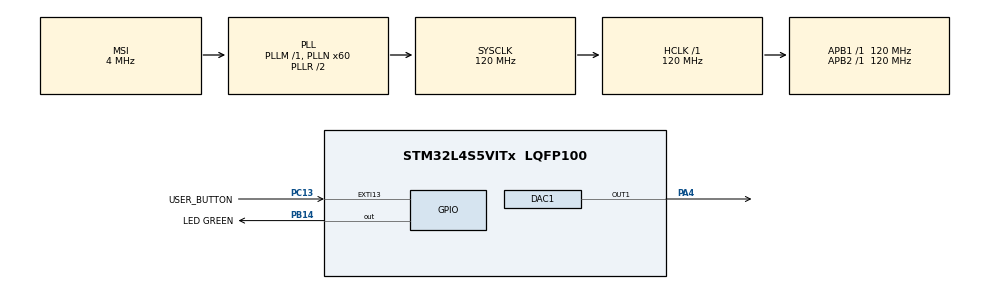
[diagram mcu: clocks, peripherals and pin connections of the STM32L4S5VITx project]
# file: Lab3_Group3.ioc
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DAC1.DAC_Trigger-DAC_OUT1=DAC_TRIGGER_T2_TRGO
Dma.DAC1_CH1.0.Direction=DMA_MEMORY_TO_PERIPH
Dma.DAC1_CH1.0.EventEnable=DISABLE
Dma.DAC1_CH1.0.Instance=DMA1_Channel1
Dma.DAC1_CH1.0.MemDataAlignment=DMA_MDATAALIGN_HALFWORD
Dma.DAC1_CH1.0.MemInc=DMA_MINC_ENABLE
Dma.DAC1_CH1.0.Mode=DMA_CIRCULAR
Dma.DAC1_CH1.0.PeriphDataAlignment=DMA_PDATAALIGN_HALFWORD
Dma.DAC1_CH1.0.PeriphInc=DMA_PINC_DISABLE
Dma.DAC1_CH1.0.Polarity=HAL_DMAMUX_REQUEST_GEN_RISING
Dma.DAC1_CH1.0.Priority=DMA_PRIORITY_LOW
Dma.DAC1_CH1.0.RequestNumber=1
Dma.DAC1_CH1.0.SignalID=NONE
Dma.DAC1_CH1.0.SyncEnable=DISABLE
Dma.DAC1_CH1.0.SyncPolarity=HAL_DMAMUX_SYNC_NO_EVENT
Dma.DAC1_CH1.0.SyncRequestNumber=1
Dma.DAC1_CH1.0.SyncSignalID=NONE
Dma.Request0=DAC1_CH1
Mcu.Family=STM32L4
Mcu.Name=STM32L4S5VITx
Mcu.Package=LQFP100
NVIC.DMA1_Channel1_IRQn=true\:0\:0\:false\:false\:true\:false\:true
NVIC.EXTI15_10_IRQn=true\:0\:0\:false\:false\:true\:true\:true
NVIC.PriorityGroup=NVIC_PRIORITYGROUP_0
NVIC.TIM2_IRQn=true\:0\:0\:false\:false\:true\:true\:true
PA13\ (JTMS/SWDIO).Mode=Serial_Wire
PA13\ (JTMS/SWDIO).Signal=SYS_JTMS-SWDIO
PA14\ (JTCK/SWCLK).Mode=Serial_Wire
PA14\ (JTCK/SWCLK).Signal=SYS_JTCK-SWCLK
PA4.Signal=COMP_DAC11_group
PB14.GPIO_Label=LED GREEN
PB14.Signal=GPIO_Output
PC13.GPIO_Label=USER_BUTTON
PC13.Signal=GPXTI13
ProjectManager.HeapSize=0x200
ProjectManager.StackSize=0x400
ProjectManager.TargetToolchain=STM32CubeIDE
RCC.ADCFreq_Value=48000000
RCC.AHBFreq_Value=120000000
RCC.APB1Freq_Value=120000000
RCC.APB1TimFreq_Value=120000000
RCC.APB2Freq_Value=120000000
RCC.APB2TimFreq_Value=120000000
RCC.CortexFreq_Value=120000000
RCC.HCLKFreq_Value=120000000
RCC.HSE_VALUE=8000000
RCC.HSI48_VALUE=48000000
RCC.HSI_VALUE=16000000
RCC.LSE_VALUE=32768
RCC.MSI_VALUE=4000000
RCC.PLLN=60
RCC.PLLSAI1N=24
RCC.SYSCLKFreq_VALUE=120000000
RCC.SYSCLKSource=RCC_SYSCLKSOURCE_PLLCLK
RCC.USBFreq_Value=48000000
RCC.VCOOutputFreq_Value=240000000
SH.COMP_DAC11_group.0=DAC1_OUT1,DAC_OUT1
TIM2.Period=2500
TIM2.TIM_MasterOutputTrigger=TIM_TRGO_UPDATE
VP_TIM2_VS_ClockSourceINT.Mode=Internal
board=B-L4S5I-IOT01A

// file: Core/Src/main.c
/* USER CODE BEGIN Header */
/**
  ******************************************************************************
  * @file           : main.c
  * @brief          : Main program body
  ******************************************************************************
  * @attention
  *
  * <h2><center>&copy; Copyright (c) 2021 STMicroelectronics.
  * All rights reserved.</center></h2>
  *
  * This software component is licensed by ST under BSD 3-Clause license,
  * the "License"; You may not use this file except in compliance with the
  * License. You may obtain a copy of the License at:
  *                        opensource.org/licenses/BSD-3-Clause
  *
  ******************************************************************************
  */
/* USER CODE END Header */
#include "main.h"

/* USER CODE BEGIN Includes */
#include "arm_math.h"
#include "lab3part1utils.h"
/* USER CODE END Includes */

/* USER CODE BEGIN PTD */
#define ITM_Port32(n) (*((volatile unsigned long *) (0xE0000000+4*n)))
/* USER CODE END PTD */

/* USER CODE BEGIN PM */
#define MAX_8 255
#define MAX_12 4095
//#define PARTONE 1
//#define PARTTWO_TIMER 2
//#define PARTTWO_DMA 3
#define PARTTWO_MOREDMA 4
/* USER CODE END PM */

DAC_HandleTypeDef hdac1;
DMA_HandleTypeDef hdma_dac1_ch1;

TIM_HandleTypeDef htim2;

void SystemClock_Config(void);
static void MX_GPIO_Init(void);
static void MX_DMA_Init(void);
static void MX_DAC1_Init(void);
static void MX_TIM2_Init(void);

/* USER CODE BEGIN 0 */
uint8_t mode = 0;
#if PARTTWO_DMA || PARTTWO_TIMER
uint8_t sin_idx = 0;
uint16_t sin_lookup_C6[45]; // 1046.5 Hz, sample rate = 48kHz
uint16_t sin_lookup_D6[40]; // 1174.66 Hz,
uint16_t sin_lookup_E6[36]; // 1318.51 Hz,
uint16_t sin_lookup_F6[34]; // 1396.91 Hz,
uint16_t sin_lookup_G6[30]; // 1567.98 Hz,
uint16_t sin_lookup_A6[27]; // 1760.00 Hz,
#else
uint16_t sin_lookup_chord[180]; // lcm(45, 36, 30)
uint16_t sin_lookup_C6[180]; // 1046.5 Hz, sample rate = 48kHz
uint16_t sin_lookup_E6[180]; // 1318.51 Hz,
uint16_t sin_lookup_G6[180]; // 1567.98 Hz,
#endif

/* USER CODE END 0 */

int main(void)
{
  /* USER CODE BEGIN 1 */
#if PARTTWO_DMA || PARTTWO_TIMER
	  uint8_t lookup_len = sizeof(sin_lookup_C6)/sizeof(sin_lookup_C6[0]);
	  for (int i = 0; i < lookup_len; i++){
	  	 sin_lookup_C6[i] = (MAX_12*0.6*(arm_sin_f32(6.283*i/lookup_len)+1));
	  }
	  lookup_len = sizeof(sin_lookup_D6)/sizeof(sin_lookup_D6[0]);
	  for (int i = 0; i < lookup_len; i++){
	  	 sin_lookup_D6[i] = (MAX_12*0.6*(arm_sin_f32(6.283*i/lookup_len)+1));
	  }
	  lookup_len = sizeof(sin_lookup_E6)/sizeof(sin_lookup_E6[0]);
	  for (int i = 0; i < lookup_len; i++){
	  	 sin_lookup_E6[i] =  (MAX_12*0.6*(arm_sin_f32(6.283*i/lookup_len)+1));
	  }
	  lookup_len = sizeof(sin_lookup_F6)/sizeof(sin_lookup_F6[0]);
	  for (int i = 0; i < lookup_len; i++){
	  	 sin_lookup_F6[i] =(MAX_12*0.6*(arm_sin_f32(6.283*i/lookup_len)+1));
	  }
	  lookup_len = sizeof(sin_lookup_G6)/sizeof(sin_lookup_G6[0]);
	  for (int i = 0; i < lookup_len; i++){
	  	 sin_lookup_G6[i] = (MAX_12*0.6*(arm_sin_f32(6.283*i/lookup_len)+1));
	  }
	  lookup_len = sizeof(sin_lookup_A6)/sizeof(sin_lookup_A6[0]);
	  for (int i = 0; i < lookup_len; i++){
	  	 sin_lookup_A6[i] = (MAX_12*0.6*(arm_sin_f32(6.283*i/lookup_len)+1));
	  }
#endif

#if PARTTWO_MOREDMA
	  int lookup_len = sizeof(sin_lookup_C6)/sizeof(sin_lookup_C6[0]);
	  	  for (int i = 0; i < lookup_len; i++){
	  	  	 sin_lookup_C6[i] = (MAX_12*0.6*(arm_sin_f32(6.283*i/45)+1));
	  	  }
		  lookup_len = sizeof(sin_lookup_E6)/sizeof(sin_lookup_E6[0]);
		  for (int i = 0; i < lookup_len; i++){
		  	 sin_lookup_E6[i] = (MAX_12*0.6*(arm_sin_f32(6.283*i/36)+1));
		  }
		  lookup_len = sizeof(sin_lookup_G6)/sizeof(sin_lookup_G6[0]);
		  for (int i = 0; i < lookup_len; i++){
		  	 sin_lookup_G6[i] = (MAX_12*0.6*(arm_sin_f32(6.283*i/30)+1));
		  }
	  lookup_len = sizeof(sin_lookup_chord)/sizeof( sin_lookup_chord[0]);
	  for (int i = 0; i < lookup_len; i++){
		  sin_lookup_chord[i] = (MAX_12*0.6*(arm_sin_f32(6.283*i/45)+1));
	  }
#endif
  /* USER CODE END 1 */

  /* MCU Configuration--------------------------------------------------------*/

  /* Reset of all peripherals, Initializes the Flash interface and the Systick. */
  HAL_Init();

  /* Configure the system clock */
  SystemClock_Config();

  /* Initialize all configured peripherals */
  MX_GPIO_Init();
  MX_DMA_Init();
  MX_DAC1_Init();
  MX_TIM2_Init();
  /* USER CODE BEGIN 2 */
  uint16_t T = 15; // f = 65 Hz, note C2
  uint16_t saw = 0;
  uint16_t tri = 0;
  uint16_t sin = 0;
  uint16_t t = 0;
#if PARTONE
  HAL_DAC_Start(&hdac1,DAC_CHANNEL_1);
  HAL_DAC_Start(&hdac1,DAC_CHANNEL_2);
#elif PARTTWO_TIMER
  HAL_DAC_Start(&hdac1,DAC_CHANNEL_1);
  HAL_TIM_Base_Start_IT(&htim2);
#elif PARTTWO_DMA
  HAL_TIM_Base_Start(&htim2);
  HAL_DAC_Start_DMA(&hdac1, DAC_CHANNEL_1, sin_lookup_C6,
  	    			sizeof(sin_lookup_C6)/sizeof(sin_lookup_C6[0]),DAC_ALIGN_12B_R);
#else
  HAL_TIM_Base_Start(&htim2);
  HAL_DAC_Start_DMA(&hdac1, DAC_CHANNEL_1, sin_lookup_chord, lookup_len, DAC_ALIGN_12B_R);
#endif
  /* USER CODE END 2 */

  /* Infinite loop */
  /* USER CODE BEGIN WHILE */
  /*** USER CODE BEGIN WHILE ***/
  while (1)
  {
	#ifdef  PARTONE
	  switch(mode) {
	     case 0:
	    	polled_waves_8bit(&tri, &saw, &sin, t, T);
	    	HAL_DAC_SetValue(&hdac1, DAC_CHANNEL_1, DAC_ALIGN_8B_R, saw);
	        break;
	     case 1:
	    	polled_waves_8bit(&tri, &saw, &sin, t, T);
	    	HAL_DAC_SetValue(&hdac1, DAC_CHANNEL_1, DAC_ALIGN_8B_R, tri);
	        break;
	     case 2:
	    	 polled_waves_8bit(&tri, &saw, &sin, t, T);
	    	HAL_DAC_SetValue(&hdac1, DAC_CHANNEL_1, DAC_ALIGN_8B_R, sin);
	        break;
	     case 3:
	    	polled_waves_12bit(&tri, &saw, &sin, t, T);
	    	HAL_DAC_SetValue(&hdac1, DAC_CHANNEL_1, DAC_ALIGN_12B_R, saw);
	        break;
	     case 4:
	    	 polled_waves_12bit(&tri, &saw, &sin, t, T);
	    	HAL_DAC_SetValue(&hdac1, DAC_CHANNEL_1, DAC_ALIGN_12B_R, tri);
	        break;
	     case 5:
	    	 polled_waves_12bit(&tri, &saw, &sin, t, T);
	    	HAL_DAC_SetValue(&hdac1, DAC_CHANNEL_1, DAC_ALIGN_12B_R, sin);
	        break;
	     default:
	    	 polled_waves_12bit(&tri, &saw, &sin, t, T);
	    	HAL_DAC_SetValue(&hdac1, DAC_CHANNEL_1, DAC_ALIGN_12B_R, sin);
	  }

	  HAL_Delay(1);
	  t++;
	  if (t > T){
		  t = 0;
	  }
	#endif
    /* USER CODE END WHILE */

  }
}

void SystemClock_Config(void)
{
  RCC_OscInitTypeDef RCC_OscInitStruct = {0};
  RCC_ClkInitTypeDef RCC_ClkInitStruct = {0};

  /** Configure the main internal regulator output voltage
  */
  if (HAL_PWREx_ControlVoltageScaling(PWR_REGULATOR_VOLTAGE_SCALE1_BOOST) != HAL_OK)
  {
    Error_Handler();
  }
  /** Initializes the RCC Oscillators according to the specified parameters
  * in the RCC_OscInitTypeDef structure.
  */
  RCC_OscInitStruct.OscillatorType = RCC_OSCILLATORTYPE_MSI;
  RCC_OscInitStruct.MSIState = RCC_MSI_ON;
  RCC_OscInitStruct.MSICalibrationValue = 0;
  RCC_OscInitStruct.MSIClockRange = RCC_MSIRANGE_6;
  RCC_OscInitStruct.PLL.PLLState = RCC_PLL_ON;
  RCC_OscInitStruct.PLL.PLLSource = RCC_PLLSOURCE_MSI;
  RCC_OscInitStruct.PLL.PLLM = 1;
  RCC_OscInitStruct.PLL.PLLN = 60;
  RCC_OscInitStruct.PLL.PLLP = RCC_PLLP_DIV2;
  RCC_OscInitStruct.PLL.PLLQ = RCC_PLLQ_DIV2;
  RCC_OscInitStruct.PLL.PLLR = RCC_PLLR_DIV2;
  if (HAL_RCC_OscConfig(&RCC_OscInitStruct) != HAL_OK)
  {
    Error_Handler();
  }
  /** Initializes the CPU, AHB and APB buses clocks
  */
  RCC_ClkInitStruct.ClockType = RCC_CLOCKTYPE_HCLK|RCC_CLOCKTYPE_SYSCLK
                              |RCC_CLOCKTYPE_PCLK1|RCC_CLOCKTYPE_PCLK2;
  RCC_ClkInitStruct.SYSCLKSource = RCC_SYSCLKSOURCE_PLLCLK;
  RCC_ClkInitStruct.AHBCLKDivider = RCC_SYSCLK_DIV1;
  RCC_ClkInitStruct.APB1CLKDivider = RCC_HCLK_DIV1;
  RCC_ClkInitStruct.APB2CLKDivider = RCC_HCLK_DIV1;

  if (HAL_RCC_ClockConfig(&RCC_ClkInitStruct, FLASH_LATENCY_5) != HAL_OK)
  {
    Error_Handler();
  }
}

static void MX_DAC1_Init(void)
{

  DAC_ChannelConfTypeDef sConfig = {0};

  /** DAC Initialization
  */
  hdac1.Instance = DAC1;
  if (HAL_DAC_Init(&hdac1) != HAL_OK)
  {
    Error_Handler();
  }
  /** DAC channel OUT1 config
  */
  sConfig.DAC_SampleAndHold = DAC_SAMPLEANDHOLD_DISABLE;
  sConfig.DAC_Trigger = DAC_TRIGGER_T2_TRGO;
  sConfig.DAC_HighFrequency = DAC_HIGH_FREQUENCY_INTERFACE_MODE_DISABLE;
  sConfig.DAC_OutputBuffer = DAC_OUTPUTBUFFER_ENABLE;
  sConfig.DAC_ConnectOnChipPeripheral = DAC_CHIPCONNECT_DISABLE;
  sConfig.DAC_UserTrimming = DAC_TRIMMING_FACTORY;
  if (HAL_DAC_ConfigChannel(&hdac1, &sConfig, DAC_CHANNEL_1) != HAL_OK)
  {
    Error_Handler();
  }
  /* USER CODE BEGIN DAC1_Init 2 */
#if PARTTWO_TIMER || PARTONE
  sConfig.DAC_Trigger = DAC_TRIGGER_NONE;
#endif
  if (HAL_DAC_ConfigChannel(&hdac1, &sConfig, DAC_CHANNEL_1) != HAL_OK)
  {
    Error_Handler();
  }

  /* USER CODE END DAC1_Init 2 */

}

static void MX_TIM2_Init(void)
{

  TIM_ClockConfigTypeDef sClockSourceConfig = {0};
  TIM_MasterConfigTypeDef sMasterConfig = {0};

  htim2.Instance = TIM2;
  htim2.Init.Prescaler = 0;
  htim2.Init.CounterMode = TIM_COUNTERMODE_UP;
  htim2.Init.Period = 2500;
  htim2.Init.ClockDivision = TIM_CLOCKDIVISION_DIV1;
  htim2.Init.AutoReloadPreload = TIM_AUTORELOAD_PRELOAD_DISABLE;
  if (HAL_TIM_Base_Init(&htim2) != HAL_OK)
  {
    Error_Handler();
  }
  sClockSourceConfig.ClockSource = TIM_CLOCKSOURCE_INTERNAL;
  if (HAL_TIM_ConfigClockSource(&htim2, &sClockSourceConfig) != HAL_OK)
  {
    Error_Handler();
  }
  sMasterConfig.MasterOutputTrigger = TIM_TRGO_UPDATE;
  sMasterConfig.MasterSlaveMode = TIM_MASTERSLAVEMODE_DISABLE;
  if (HAL_TIMEx_MasterConfigSynchronization(&htim2, &sMasterConfig) != HAL_OK)
  {
    Error_Handler();
  }

}

static void MX_DMA_Init(void)
{

  /* DMA controller clock enable */
  __HAL_RCC_DMAMUX1_CLK_ENABLE();
  __HAL_RCC_DMA1_CLK_ENABLE();

  /* DMA interrupt init */
  /* DMA1_Channel1_IRQn interrupt configuration */
  HAL_NVIC_SetPriority(DMA1_Channel1_IRQn, 0, 0);
  HAL_NVIC_EnableIRQ(DMA1_Channel1_IRQn);

}

static void MX_GPIO_Init(void)
{
  GPIO_InitTypeDef GPIO_InitStruct = {0};

  /* GPIO Ports Clock Enable */
  __HAL_RCC_GPIOC_CLK_ENABLE();
  __HAL_RCC_GPIOA_CLK_ENABLE();
  __HAL_RCC_GPIOB_CLK_ENABLE();

  /*Configure GPIO pin Output Level */
  HAL_GPIO_WritePin(LED_GREEN_GPIO_Port, LED_GREEN_Pin, GPIO_PIN_RESET);

  /*Configure GPIO pin : USER_BUTTON_Pin */
  GPIO_InitStruct.Pin = USER_BUTTON_Pin;
  GPIO_InitStruct.Mode = GPIO_MODE_IT_RISING;
  GPIO_InitStruct.Pull = GPIO_NOPULL;
  HAL_GPIO_Init(USER_BUTTON_GPIO_Port, &GPIO_InitStruct);

  /*Configure GPIO pin : LED_GREEN_Pin */
  GPIO_InitStruct.Pin = LED_GREEN_Pin;
  GPIO_InitStruct.Mode = GPIO_MODE_OUTPUT_PP;
  GPIO_InitStruct.Pull = GPIO_NOPULL;
  GPIO_InitStruct.Speed = GPIO_SPEED_FREQ_LOW;
  HAL_GPIO_Init(LED_GREEN_GPIO_Port, &GPIO_InitStruct);

  /* EXTI interrupt init*/
  HAL_NVIC_SetPriority(EXTI15_10_IRQn, 0, 0);
  HAL_NVIC_EnableIRQ(EXTI15_10_IRQn);

}

/* USER CODE BEGIN 4 */
#if PARTTWO_DMA || PARTTWO_TIMER
void HAL_GPIO_EXTI_Callback(uint16_t GPIO_Pin){
	if(GPIO_Pin == USER_BUTTON_Pin){
		HAL_GPIO_TogglePin(LED_GREEN_GPIO_Port, LED_GREEN_Pin);
		mode = (mode+1)%6;
	}
	switch(mode) {
	     case 0:
	    	HAL_DAC_Stop_DMA(&hdac1, DAC_CHANNEL_1);
	    	HAL_DAC_Start_DMA(&hdac1, DAC_CHANNEL_1, sin_lookup_C6,
	    			sizeof(sin_lookup_C6)/sizeof(sin_lookup_C6[0]),DAC_ALIGN_12B_R);
	        break;
	     case 1:
	    	HAL_DAC_Stop_DMA(&hdac1, DAC_CHANNEL_1);
	    	HAL_DAC_Start_DMA(&hdac1, DAC_CHANNEL_1, sin_lookup_D6,
	    			sizeof(sin_lookup_D6)/sizeof(sin_lookup_D6[0]),DAC_ALIGN_12B_R);
	        break;
	     case 2:
	    	HAL_DAC_Stop_DMA(&hdac1, DAC_CHANNEL_1);
	    	HAL_DAC_Start_DMA(&hdac1, DAC_CHANNEL_1, sin_lookup_E6,
	    			sizeof(sin_lookup_E6)/sizeof(sin_lookup_E6[0]),DAC_ALIGN_12B_R);
	        break;
	     case 3:
	    	 HAL_DAC_Stop_DMA(&hdac1, DAC_CHANNEL_1);
	    	 HAL_DAC_Start_DMA(&hdac1, DAC_CHANNEL_1, sin_lookup_F6,
		    			sizeof(sin_lookup_F6)/sizeof(sin_lookup_F6[0]),DAC_ALIGN_12B_R);
	        break;
	     case 4:
	    	 HAL_DAC_Stop_DMA(&hdac1, DAC_CHANNEL_1);
	    	 HAL_DAC_Start_DMA(&hdac1, DAC_CHANNEL_1, sin_lookup_G6,
		    			sizeof(sin_lookup_G6)/sizeof(sin_lookup_G6[0]),DAC_ALIGN_12B_R);

	        break;
	     case 5:
	    	 HAL_DAC_Stop_DMA(&hdac1, DAC_CHANNEL_1);
	    	 HAL_DAC_Start_DMA(&hdac1, DAC_CHANNEL_1, sin_lookup_A6,
		    			sizeof(sin_lookup_A6)/sizeof(sin_lookup_A6[0]),DAC_ALIGN_12B_R);
	        break;
	     default:
	    	 HAL_DAC_Stop_DMA(&hdac1, DAC_CHANNEL_1);
	    	 HAL_DAC_Start_DMA(&hdac1, DAC_CHANNEL_1, sin_lookup_C6,
		    			sizeof(sin_lookup_C6)/sizeof(sin_lookup_C6[0]),DAC_ALIGN_12B_R);
	  }

}
#endif

#ifdef PARTTWO_MOREDMA
void HAL_GPIO_EXTI_Callback(uint16_t GPIO_Pin){
	if(GPIO_Pin == USER_BUTTON_Pin){
		HAL_GPIO_TogglePin(LED_GREEN_GPIO_Port, LED_GREEN_Pin);
		mode = (mode+1)%3;
	}

}

void HAL_DAC_ConvHalfCpltCallbackCh1(DAC_HandleTypeDef *hdac){
	ITM_Port32(31) = 11111;
	switch(mode) {
	case 0:
		memcpy(sin_lookup_chord, sin_lookup_C6, sizeof(sin_lookup_chord)/2);
	  break;
	case 1:
		memcpy(sin_lookup_chord, sin_lookup_E6, sizeof(sin_lookup_chord)/2);
		  break;
	case 2:
		memcpy(sin_lookup_chord, sin_lookup_G6, sizeof(sin_lookup_chord)/2);
		  break;
	default:
		memcpy(sin_lookup_chord, sin_lookup_C6, sizeof(sin_lookup_chord)/2);
		  break;

	}
}

void HAL_DAC_ConvCpltCallbackCh1(DAC_HandleTypeDef *hdac){
	int lookup_len = sizeof(sin_lookup_chord)/sizeof( sin_lookup_chord[0]);
	ITM_Port32(31) = 22222;
	switch(mode) {
	case 0:
		memcpy(sin_lookup_chord+lookup_len/2, sin_lookup_C6+lookup_len/2, sizeof(sin_lookup_chord)/2);
	  break;
	case 1:
		memcpy(sin_lookup_chord+lookup_len/2, sin_lookup_E6+lookup_len/2, sizeof(sin_lookup_chord)/2);
		  break;
	case 2:
		memcpy(sin_lookup_chord+lookup_len/2, sin_lookup_G6+lookup_len/2, sizeof(sin_lookup_chord)/2);
		  break;
	default:
		memcpy(sin_lookup_chord+lookup_len/2, sin_lookup_C6+lookup_len/2, sizeof(sin_lookup_chord)/2);
		  break;

	}
}

#endif

#ifdef PARTTWO_TIMER
void HAL_TIM_PeriodElapsedCallback(TIM_HandleTypeDef *htim){
	if (htim == &htim2){
		switch(mode) {
		     case 0:
		 		HAL_DAC_SetValue(&hdac1, DAC_CHANNEL_1, DAC_ALIGN_12B_R, sin_lookup_C6[sin_idx]);
		 		sin_idx++;
		 		if (sin_idx == sizeof(sin_lookup_C6)/sizeof(sin_lookup_C6[0])){
		 			sin_idx = 0;
		 		}
		        break;
		     case 1:
		 		HAL_DAC_SetValue(&hdac1, DAC_CHANNEL_1, DAC_ALIGN_12B_R, sin_lookup_D6[sin_idx]);
		 		sin_idx++;
		 		if (sin_idx == sizeof(sin_lookup_D6)/sizeof(sin_lookup_D6[0])){
		 			sin_idx = 0;
		 		}
		        break;
		     case 2:
		    	HAL_DAC_SetValue(&hdac1, DAC_CHANNEL_1, DAC_ALIGN_12B_R, sin_lookup_E6[sin_idx]);
		 		sin_idx++;
		 		if (sin_idx == sizeof(sin_lookup_E6)/sizeof(sin_lookup_E6[0])){
		 			sin_idx = 0;
		 		}

		        break;
		     case 3:
		    	HAL_DAC_SetValue(&hdac1, DAC_CHANNEL_1, DAC_ALIGN_12B_R, sin_lookup_F6[sin_idx]);
		 		sin_idx++;
		 		if (sin_idx == sizeof(sin_lookup_F6)/sizeof(sin_lookup_F6[0])){
		 			sin_idx = 0;
		 		}
		 		break;
		     case 4:
		    	HAL_DAC_SetValue(&hdac1, DAC_CHANNEL_1, DAC_ALIGN_12B_R, sin_lookup_G6[sin_idx]);
		 		sin_idx++;
		 		if (sin_idx == sizeof(sin_lookup_G6)/sizeof(sin_lookup_G6[0])){
		 			sin_idx = 0;
		 		}
		        break;
		     case 5:
		    	HAL_DAC_SetValue(&hdac1, DAC_CHANNEL_1, DAC_ALIGN_12B_R, sin_lookup_A6[sin_idx]);
		 		sin_idx++;
		 		if (sin_idx == sizeof(sin_lookup_A6)/sizeof(sin_lookup_A6[0])){
		 			sin_idx = 0;
		 		}
		 		break;
		     default:
		    	 HAL_DAC_SetValue(&hdac1, DAC_CHANNEL_1, DAC_ALIGN_12B_R, sin_lookup_C6[sin_idx]);
		 		sin_idx++;
		 		if (sin_idx == sizeof(sin_lookup_C6)/sizeof(sin_lookup_C6[0])){
		 			sin_idx = 0;
		 		}
		}

	}

}
#endif

/* USER CODE END 4 */

void Error_Handler(void)
{
  __disable_irq();
  while (1)
  {
  }
}

/************************ (C) COPYRIGHT STMicroelectronics *****END OF FILE****/
